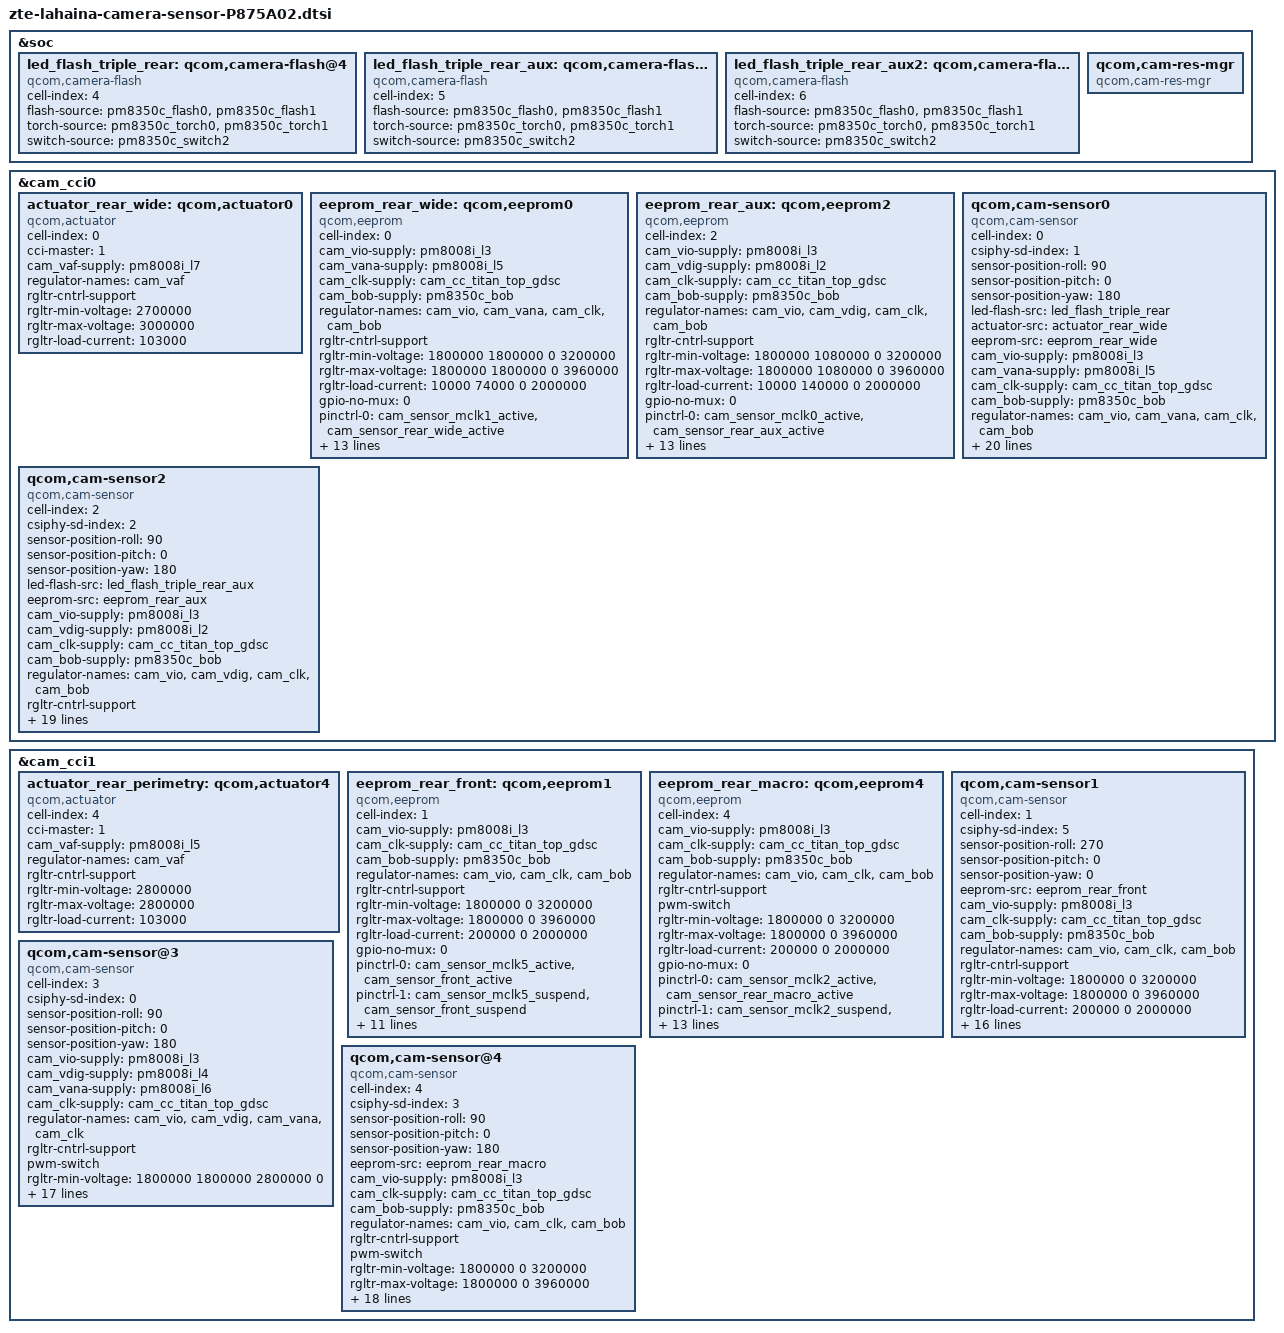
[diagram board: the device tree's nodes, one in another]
#include <dt-bindings/clock/qcom,camcc-lahaina.h>

&soc {
	led_flash_triple_rear: qcom,camera-flash@4 {
		cell-index = <4>;
		compatible = "qcom,camera-flash";
		flash-source = <&pm8350c_flash0 &pm8350c_flash1>;
		torch-source = <&pm8350c_torch0 &pm8350c_torch1>;
		switch-source = <&pm8350c_switch2>;
		status = "ok";
	};

	led_flash_triple_rear_aux: qcom,camera-flash@5 {
		cell-index = <5>;
		compatible = "qcom,camera-flash";
		flash-source = <&pm8350c_flash0 &pm8350c_flash1>;
		torch-source = <&pm8350c_torch0 &pm8350c_torch1>;
		switch-source = <&pm8350c_switch2>;
		status = "ok";
	};

	led_flash_triple_rear_aux2: qcom,camera-flash@6 {
		cell-index = <6>;
		compatible = "qcom,camera-flash";
		flash-source = <&pm8350c_flash0 &pm8350c_flash1>;
		torch-source = <&pm8350c_torch0 &pm8350c_torch1>;
		switch-source = <&pm8350c_switch2>;
		status = "ok";
	};

	qcom,cam-res-mgr {
		compatible = "qcom,cam-res-mgr";
		status = "ok";
	};
};

&cam_cci0 {
	actuator_rear_wide: qcom,actuator0 {
		cell-index = <0>;
		compatible = "qcom,actuator";
		cci-master = <1>;
		cam_vaf-supply = <&pm8008i_l7>;
		regulator-names = "cam_vaf";
		rgltr-cntrl-support;
		rgltr-min-voltage = <2700000>;
		rgltr-max-voltage = <3000000>;
		rgltr-load-current = <103000>;
	};

	eeprom_rear_wide: qcom,eeprom0 {
		cell-index = <0>;
		compatible = "qcom,eeprom";
		cam_vio-supply = <&pm8008i_l3>;
		cam_vana-supply = <&pm8008i_l5>;
		cam_clk-supply = <&cam_cc_titan_top_gdsc>;
		cam_bob-supply = <&pm8350c_bob>;
		regulator-names = "cam_vio", "cam_vana", "cam_clk", "cam_bob";
		rgltr-cntrl-support;
		rgltr-min-voltage = <1800000 1800000 0 3200000>;
		rgltr-max-voltage = <1800000 1800000 0 3960000>;
		rgltr-load-current = <10000 74000 0 2000000>;
		gpio-no-mux = <0>;
		pinctrl-names = "cam_default", "cam_suspend";
		pinctrl-0 = <&cam_sensor_mclk1_active
				 &cam_sensor_rear_wide_active>;
		pinctrl-1 = <&cam_sensor_mclk1_suspend
				 &cam_sensor_rear_wide_suspend>;
		gpios = <&tlmm 101 0>,
			<&tlmm 16 0>,
			<&tlmm 124 0>;
		gpio-reset = <1>;
		gpio-custom1 = <2>;
		gpio-req-tbl-num = <0 1 2>;
		gpio-req-tbl-flags = <1 0 0>;
		gpio-req-tbl-label = "CAMIF_MCLK1",
					"CAM_RESET0",
					"CAM_AVDD0";
		cci-master = <1>;
		status = "ok";
		clocks = <&clock_camcc CAM_CC_MCLK1_CLK>;
		clock-names = "cam_clk";
		clock-cntl-level = "nominal";
		clock-rates = <24000000>;
	};

	eeprom_rear_aux: qcom,eeprom2 {
		cell-index = <2>;
		compatible = "qcom,eeprom";
		cam_vio-supply = <&pm8008i_l3>;
		cam_vdig-supply = <&pm8008i_l2>;
		cam_clk-supply = <&cam_cc_titan_top_gdsc>;
		cam_bob-supply = <&pm8350c_bob>;
		regulator-names = "cam_vio", "cam_vdig", "cam_clk",
			"cam_bob";
		rgltr-cntrl-support;
		rgltr-min-voltage = <1800000 1080000 0 3200000>;
		rgltr-max-voltage = <1800000 1080000 0 3960000>;
		rgltr-load-current = <10000 140000 0 2000000>;
		gpio-no-mux = <0>;
		pinctrl-names = "cam_default", "cam_suspend";
		pinctrl-0 = <&cam_sensor_mclk0_active
				 &cam_sensor_rear_aux_active>;
		pinctrl-1 = <&cam_sensor_mclk0_suspend
				 &cam_sensor_rear_aux_suspend>;
		gpios = <&tlmm 100 0>,
			<&tlmm 17 0>,
			<&tlmm 27 0>;
		gpio-reset = <1>;
		gpio-custom1 = <2>;
		gpio-req-tbl-num = <0 1 2>;
		gpio-req-tbl-flags = <1 0 0>;
		gpio-req-tbl-label = "CAMIF_MCLK0",
					"CAM_RESET0",
					"CAM_VANA2";
		cci-master = <0>;
		status = "ok";
		clocks = <&clock_camcc CAM_CC_MCLK0_CLK>;
		clock-names = "cam_clk";
		clock-cntl-level = "nominal";
		clock-rates = <24000000>;
	};

	qcom,cam-sensor0 {
		cell-index = <0>;
		compatible = "qcom,cam-sensor";
		csiphy-sd-index = <1>;
		sensor-position-roll = <90>;
		sensor-position-pitch = <0>;
		sensor-position-yaw = <180>;
		led-flash-src = <&led_flash_triple_rear>;
		actuator-src = <&actuator_rear_wide>;
		eeprom-src = <&eeprom_rear_wide>;
		cam_vio-supply = <&pm8008i_l3>;
		cam_vana-supply = <&pm8008i_l5>;
		cam_clk-supply = <&cam_cc_titan_top_gdsc>;
		cam_bob-supply = <&pm8350c_bob>;
		regulator-names = "cam_vio", "cam_vana", "cam_clk",
			"cam_bob";
		rgltr-cntrl-support;
		rgltr-min-voltage = <1800000 1800000 0 3200000>;
		rgltr-max-voltage = <1800000 1800000 0 3960000>;
		rgltr-load-current = <10000 74000 0 2000000>;
		gpio-no-mux = <0>;
		pinctrl-names = "cam_default", "cam_suspend";
		pinctrl-0 = <&cam_sensor_mclk1_active
				&cam_sensor_rear_wide_active>;
		pinctrl-1 = <&cam_sensor_mclk1_suspend
				&cam_sensor_rear_wide_suspend>;
		gpios = <&tlmm 101 0>,
			<&tlmm 16 0>,
			<&tlmm 124 0>;
		gpio-reset = <1>;
		gpio-custom1 = <2>;
		gpio-req-tbl-num = <0 1 2>;
		gpio-req-tbl-flags = <1 0 0>;
		gpio-req-tbl-label = "CAMIF_MCLK1",
					"CAM_RESET0",
					"CAM_AVDD0";
		cci-master = <1>;
		status = "ok";
		clocks = <&clock_camcc CAM_CC_MCLK1_CLK>;
		clock-names = "cam_clk";
		clock-cntl-level = "nominal";
		clock-rates = <24000000>;
	};

	qcom,cam-sensor2 {
		cell-index = <2>;
		compatible = "qcom,cam-sensor";
		csiphy-sd-index = <2>;
		sensor-position-roll = <90>;
		sensor-position-pitch = <0>;
		sensor-position-yaw = <180>;
		led-flash-src = <&led_flash_triple_rear_aux>;
		eeprom-src = <&eeprom_rear_aux>;
		cam_vio-supply = <&pm8008i_l3>;
		cam_vdig-supply = <&pm8008i_l2>;
		cam_clk-supply = <&cam_cc_titan_top_gdsc>;
		cam_bob-supply = <&pm8350c_bob>;
		regulator-names = "cam_vio", "cam_vdig", "cam_clk",
			"cam_bob";
		rgltr-cntrl-support;
		rgltr-min-voltage = <1800000 1080000 0 3200000>;
		rgltr-max-voltage = <1800000 1080000 0 3960000>;
		rgltr-load-current = <10000 140000 0 2000000>;
		gpio-no-mux = <0>;
		pinctrl-names = "cam_default", "cam_suspend";
		pinctrl-0 = <&cam_sensor_mclk0_active
				 &cam_sensor_rear_aux_active>;
		pinctrl-1 = <&cam_sensor_mclk0_suspend
				 &cam_sensor_rear_aux_suspend>;
		gpios = <&tlmm 100 0>,
			<&tlmm 17 0>,
			<&tlmm 27 0>;
		gpio-reset = <1>;
		gpio-custom1 = <2>;
		gpio-req-tbl-num = <0 1 2>;
		gpio-req-tbl-flags = <1 0 0>;
		gpio-req-tbl-label = "CAMIF_MCLK0",
					"CAM_RESET0",
					"CAM_VANA2";
		cci-master = <0>;
		status = "ok";
		clocks = <&clock_camcc CAM_CC_MCLK0_CLK>;
		clock-names = "cam_clk";
		clock-cntl-level = "nominal";
		clock-rates = <24000000>;
	};
};

&cam_cci1 {
	actuator_rear_perimetry: qcom,actuator4 {
		cell-index = <4>;
		compatible = "qcom,actuator";
		cci-master = <1>;
		cam_vaf-supply = <&pm8008i_l5>;
		regulator-names = "cam_vaf";
		rgltr-cntrl-support;
		rgltr-min-voltage = <2800000>;
		rgltr-max-voltage = <2800000>;
		rgltr-load-current = <103000>;
	};

	eeprom_rear_front: qcom,eeprom1 {
		cell-index = <1>;
		compatible = "qcom,eeprom";
		cam_vio-supply = <&pm8008i_l3>;
		cam_clk-supply = <&cam_cc_titan_top_gdsc>;
		cam_bob-supply = <&pm8350c_bob>;
		regulator-names = "cam_vio", "cam_clk", "cam_bob";
		rgltr-cntrl-support;
		rgltr-min-voltage = <1800000 0 3200000>;
		rgltr-max-voltage = <1800000 0 3960000>;
		rgltr-load-current = <200000 0 2000000>;
		gpio-no-mux = <0>;
		pinctrl-names = "cam_default", "cam_suspend";
		pinctrl-0 = <&cam_sensor_mclk5_active
				 &cam_sensor_front_active>;
		pinctrl-1 = <&cam_sensor_mclk5_suspend
				 &cam_sensor_front_suspend>;
		gpios = <&tlmm 105 0>,
			<&tlmm 115 0>,
			<&tlmm 123 0>;
		gpio-reset = <1>;
		gpio-custom1 = <2>;
		gpio-req-tbl-num = <0 1 2>;
		gpio-req-tbl-flags = <1 0 0>;
		gpio-req-tbl-label = "CAMIF_MCLK5",
					"CAM_RESET5",
					"CAM_VANA1";
		cci-master = <1>;
		status = "ok";
		clocks = <&clock_camcc CAM_CC_MCLK5_CLK>;
		clock-names = "cam_clk";
		clock-cntl-level = "nominal";
		clock-rates = <24000000>;
	};

	eeprom_rear_macro: qcom,eeprom4 {
		cell-index = <4>;
		compatible = "qcom,eeprom";
		cam_vio-supply = <&pm8008i_l3>;
		cam_clk-supply = <&cam_cc_titan_top_gdsc>;
		cam_bob-supply = <&pm8350c_bob>;
		regulator-names = "cam_vio", "cam_clk", "cam_bob";
		rgltr-cntrl-support;
		pwm-switch;
		rgltr-min-voltage = <1800000 0 3200000>;
		rgltr-max-voltage = <1800000 0 3960000>;
		rgltr-load-current = <200000 0 2000000>;
		gpio-no-mux = <0>;
		pinctrl-names = "cam_default", "cam_suspend";
		pinctrl-0 = <&cam_sensor_mclk2_active
			&cam_sensor_rear_macro_active>;
		pinctrl-1 = <&cam_sensor_mclk2_suspend
			&cam_sensor_rear_macro_suspend>;
		gpios = <&tlmm 102 0>,
			<&tlmm 106 0>,
			<&tlmm 131 0>;
		gpio-reset = <1>;
		gpio-custom1 = <2>;
		gpio-req-tbl-num = <0 1 2>;
		gpio-req-tbl-flags = <1 0 0>;
		gpio-req-tbl-label = "CAMIF_MCLK2",
					"CAM_RESET2",
					"CAM_AVDD2";
		sensor-mode = <0>;
		cci-master = <0>;
		clocks = <&clock_camcc CAM_CC_MCLK2_CLK>;
		clock-names = "cam_clk";
		clock-cntl-level = "nominal";
		status = "ok";
		clock-rates = <24000000>;
	};

	qcom,cam-sensor1 {
		cell-index = <1>;
		compatible = "qcom,cam-sensor";
		csiphy-sd-index = <5>;
		sensor-position-roll = <270>;
		sensor-position-pitch = <0>;
		sensor-position-yaw = <0>;
		eeprom-src = <&eeprom_rear_front>;
		cam_vio-supply = <&pm8008i_l3>;
		cam_clk-supply = <&cam_cc_titan_top_gdsc>;
		cam_bob-supply = <&pm8350c_bob>;
		regulator-names = "cam_vio", "cam_clk", "cam_bob";
		rgltr-cntrl-support;
		rgltr-min-voltage = <1800000 0 3200000>;
		rgltr-max-voltage = <1800000 0 3960000>;
		rgltr-load-current = <200000 0 2000000>;
		gpio-no-mux = <0>;
		pinctrl-names = "cam_default", "cam_suspend";
		pinctrl-0 = <&cam_sensor_mclk5_active
				 &cam_sensor_front_active>;
		pinctrl-1 = <&cam_sensor_mclk5_suspend
				 &cam_sensor_front_suspend>;
		gpios = <&tlmm 105 0>,
			<&tlmm 115 0>,
			<&tlmm 123 0>;
		gpio-reset = <1>;
		gpio-custom1 = <2>;
		gpio-req-tbl-num = <0 1 2>;
		gpio-req-tbl-flags = <1 0 0>;
		gpio-req-tbl-label = "CAMIF_MCLK5",
					"CAM_RESET5",
					"CAM_VANA1";
		cci-master = <1>;
		status = "ok";
		clocks = <&clock_camcc CAM_CC_MCLK5_CLK>;
		clock-names = "cam_clk";
		clock-cntl-level = "nominal";
		clock-rates = <24000000>;
	};

	qcom,cam-sensor@3 {
		cell-index = <3>;
		compatible = "qcom,cam-sensor";
		csiphy-sd-index = <0>;
		sensor-position-roll = <90>;
		sensor-position-pitch = <0>;
		sensor-position-yaw = <180>;
		cam_vio-supply = <&pm8008i_l3>;
		cam_vdig-supply = <&pm8008i_l4>;
		cam_vana-supply = <&pm8008i_l6>;
		cam_clk-supply = <&cam_cc_titan_top_gdsc>;
		regulator-names = "cam_vio", "cam_vdig",
			"cam_vana", "cam_clk";
		rgltr-cntrl-support;
		pwm-switch;
		rgltr-min-voltage = <1800000 1800000 2800000 0>;
		rgltr-max-voltage = <1800000 1800000 2800000 0>;
		rgltr-load-current = <200000 805000 50000 0>;
		gpio-no-mux = <0>;
		pinctrl-names = "cam_default", "cam_suspend";
		pinctrl-0 = <&cam_sensor_mclk3_active
				 &cam_sensor_depth_active>;
		pinctrl-1 = <&cam_sensor_mclk3_suspend
				 &cam_sensor_depth_suspend>;
		gpios = <&tlmm 103 0>,
			<&tlmm 117 0>;
		gpio-reset = <1>;
		gpio-req-tbl-num = <0 1>;
		gpio-req-tbl-flags = <1 0>;
		gpio-req-tbl-label = "CAMIF_MCLK3",
					"CAM_RESET3";
		sensor-mode = <0>;
		cci-master = <1>;
		clocks = <&clock_camcc CAM_CC_MCLK3_CLK>;
		clock-names = "cam_clk";
		clock-cntl-level = "nominal";
		status = "ok";
		clock-rates = <24000000>;
	};

	qcom,cam-sensor@4 {
		cell-index = <4>;
		compatible = "qcom,cam-sensor";
		csiphy-sd-index = <3>;
		sensor-position-roll = <90>;
		sensor-position-pitch = <0>;
		sensor-position-yaw = <180>;
		eeprom-src = <&eeprom_rear_macro>;
		cam_vio-supply = <&pm8008i_l3>;
		cam_clk-supply = <&cam_cc_titan_top_gdsc>;
		cam_bob-supply = <&pm8350c_bob>;
		regulator-names = "cam_vio", "cam_clk", "cam_bob";
		rgltr-cntrl-support;
		pwm-switch;
		rgltr-min-voltage = <1800000 0 3200000>;
		rgltr-max-voltage = <1800000 0 3960000>;
		rgltr-load-current = <200000 0 2000000>;
		gpio-no-mux = <0>;
		pinctrl-names = "cam_default", "cam_suspend";
		pinctrl-0 = <&cam_sensor_mclk2_active
				 &cam_sensor_rear_macro_active>;
		pinctrl-1 = <&cam_sensor_mclk2_suspend
				 &cam_sensor_rear_macro_suspend>;
		gpios = <&tlmm 102 0>,
			<&tlmm 106 0>,
			<&tlmm 131 0>;
		gpio-reset = <1>;
		gpio-custom1 = <2>;
		gpio-req-tbl-num = <0 1 2>;
		gpio-req-tbl-flags = <1 0 0>;
		gpio-req-tbl-label = "CAMIF_MCLK2",
					"CAM_RESET2",
					"CAM_AVDD2";
		sensor-mode = <0x0>;
		cci-master = <0>;
		clocks = <&clock_camcc CAM_CC_MCLK2_CLK>;
		clock-names = "cam_clk";
		clock-cntl-level = "nominal";
		status = "ok";
		clock-rates = <24000000>;
	};
};
